# K1921VG015 register map
Vendor: NIIET; Series: K1921Vxxx; File version: 1.14
Registers are 32-bit, read-write, reset 0x0 unless marked. A register's access mark holds for its fields unless they carry their own. Offsets are from the block's base; [hi:lo] are bit positions; lines under a group give offsets from that group; {n}, {i} and the like mark numbered series.

## USB — USB control registers
Base 0x20010000
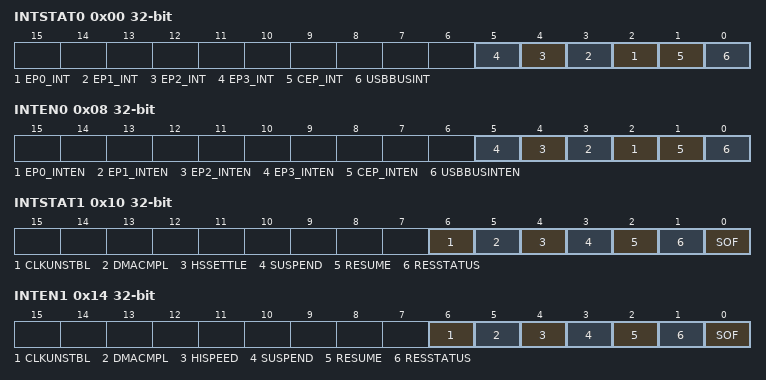
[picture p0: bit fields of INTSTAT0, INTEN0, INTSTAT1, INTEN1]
0x00 INTSTAT0 — Interrupt status register
  [n+2] EP{n}_INT (n=0..3) — Interrupt flags EndPoint {n}
  [1] CEP_INT — Interrupt flag Control EndPoint
  [0] USBBUSINT — Interrupt flag events on the USB bus
0x08 INTEN0 — Interrupt enable register
  [n+2] EP{n}_INTEN (n=0..3) — Interrupt enable for EndPoint {n}
  [1] CEP_INTEN — Interrupt enable for Control EndPoint
  [0] USBBUSINTEN — Enable interrupts from the events on the USB bus
0x10 INTSTAT1 — USB Interrupt status register
  [6] CLKUNSTBL — Interrupt flag, signaling an unstable clock signal UTMI and to initialize the device controller registers
  [5] DMACMPL — Completion flag DMA data transfer
  [4] HSSETTLE — Completion flag reset and switching devices in high-speed mode
  [3] SUSPEND — SUSPEND mode request bit
  [2] RESUME — Flag reactivate the device
  [1] RESSTATUS — Completion flag reset the root port
  [0] SOF — Flag SOF packet reception
0x14 INTEN1 — USB Interrupt enable register
  [6] CLKUNSTBL — Enable interrupt, signaling an unstable clock signal UTMI and to initialize the device controller registers
  [5] DMACMPL — Enable completion DMA data transfer
  [4] HISPEED — Enable completion reset and switching devices in high-speed mode
  [3] SUSPEND — Enable SUSPEND mode request bit
  [2] RESUME — Enable reactivate the device
  [1] RESSTATUS — Enable completion reset the root port
  [0] SOF — Enable SOF packet reception
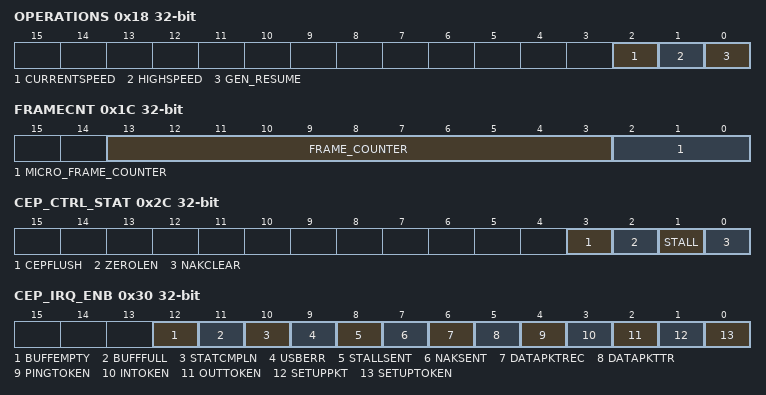
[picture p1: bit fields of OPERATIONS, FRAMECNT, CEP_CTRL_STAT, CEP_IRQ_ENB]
0x18 OPERATIONS — USB Operations register
  [2] CURRENTSPEED ro — Speed indication device controller 1-High speed; 0 - Full speed
  [1] HIGHSPEED ro — Trigger bit protocol 'Chirp'
  [0] GEN_RESUME — Bit start recovery work
0x1C FRAMECNT ro — USB Frame counter register
  [13:3] FRAME_COUNTER — Field frame counter since last SOF packet
  [2:0] MICRO_FRAME_COUNTER — Number field current a chip
0x20 USBADDR — USB Address register
  [6:0] USBADDR — Field of the current address of the device
0x28 CEP_DATA_BUF — Data buffer for transmission register of Control EndPoint
  [15:0] VAL — Data buffer for transmission
0x2C CEP_CTRL_STAT — Control register and buffer status of Control EndPoint
  [3] CEPFLUSH — Reset buffer
  [2] ZEROLEN — Enable transmission zero length packet
  [1] STALL — Enable sending 'Stall'
  [0] NAKCLEAR — Receiving flag tags SETIP
0x30 CEP_IRQ_ENB — Interrupt Enable buffer register of Control EndPoint
  [12] BUFFEMPTY — Enable flag emptying control buffer
  [11] BUFFFULL — Enable flag filling control buffer
  [10] STATCMPLN — Enable flag successful completion stage 'Status' operations on the USB bus
  [9] USBERR — Enable error flag during the operation
  [8] STALLSENT — Enable flag closure parcel labels STALL in response to mark IN or OUT
  [7] NAKSENT — Enable flag closure parcel labels NAK in response to mark IN or OUT
  [6] DATAPKTREC — Enable flag successful reception of the data packet following the label OUT, in response to which the mark has been sent ACK
  [5] DATAPKTTR — Enable flag successful sending of the data packet in response to the label to obtain IN ACK confirming tags
  [4] PINGTOKEN — Enable reception end flag tags PING from host
  [3] INTOKEN — Enable reception end flag tags IN from the host
  [2] OUTTOKEN — Enable reception end flag tags OUT from the host
  [1] SETUPPKT — Enable flag deadline Setup package from the host
  [0] SETUPTOKEN — Enable flag deadline tags SETUP from the host
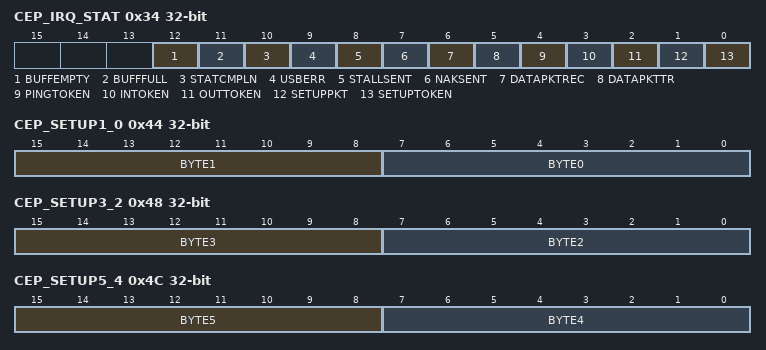
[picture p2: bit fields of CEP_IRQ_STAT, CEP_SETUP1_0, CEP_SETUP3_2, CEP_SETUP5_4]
0x34 CEP_IRQ_STAT — Buffer interrupt flag register of Control EndPoint
  [12] BUFFEMPTY ro — Flag control buffer emptying
  [11] BUFFFULL ro — Flag filling control buffer
  [10] STATCMPLN — Flag successful completion stage 'Status' operations on the USB bus
  [9] USBERR — The error flag during the operation
  [8] STALLSENT — Flag closure parcel labels STALL in response to mark IN or OUT
  [7] NAKSENT — Flag closure parcel labels NAK in response to mark IN or OUT
  [6] DATAPKTREC — Flag successful reception of the data packet following the label OUT, in response to which the mark has been sent ACK
  [5] DATAPKTTR — Flag successful sending of the data packet in response to the label to obtain IN ACK confirming tags
  [4] PINGTOKEN — Reception end flag tags PING from host
  [3] INTOKEN — Reception end flag tags IN from the host
  [2] OUTTOKEN — Reception end flag tags OUT from the host
  [1] SETUPPKT — Flag deadline Setup package from the host
  [0] SETUPTOKEN — Flag deadline tags SETUP from the host
0x38 CEP_IN_XFRCNT — In transfer data count register of Control EndPoint
  [7:0] DATACOUNT — The number of bytes to be sent in response to a label IN
0x3C CEP_OUT_XFRCNT ro — Out-transfer data count register of Control EndPoint
  [7:0] DATACOUNT — The number of bytes received of data
0x40 CEP_DATA_AVL ro — Register number of bytes received
  [15:0] NUM_BYTES — The number of bytes received of data
0x44 CEP_SETUP1_0 ro — Register zero and first byte packet Setup of Control EndPoint
  [15:8] BYTE1 — The first byte of the packet Setup
  [7:0] BYTE0 — destination
0x48 CEP_SETUP3_2 ro — Register 2nd and 3rd bytes of the packet Setup of Control EndPoint
  [15:8] BYTE3 — High byte field wValue
  [7:0] BYTE2 — Low byte field wValue
0x4C CEP_SETUP5_4 ro — Register 4th and 5th bytes of the packet Setup of Control EndPoint
  [15:8] BYTE5 — High byte field windex
  [7:0] BYTE4 — Low byte field windex
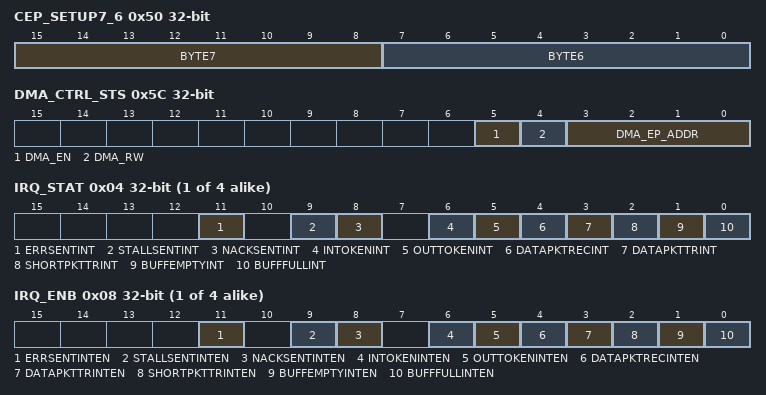
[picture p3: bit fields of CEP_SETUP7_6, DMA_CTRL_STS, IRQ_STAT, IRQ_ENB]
0x50 CEP_SETUP7_6 ro — Register on the 6th and 7th byte packet Setup of Control EndPoint
  [15:8] BYTE7 — High byte field wLength
  [7:0] BYTE6 — Low byte field wLength
0x54 CEP_START_ADDR — Control EndPoint RAM start Addr register
  [15:0] VAL — Beginning of the address space
0x58 CEP_END_ADDR — Control EndPoint RAM end Addr register
  [15:0] VAL — The end of the address space
0x5C DMA_CTRL_STS — DMA Control Register
  [5] DMA_EN — Enable DMA
  [4] DMA_RW — Type DMA operations 1-Read, 0-Write
  [3:0] DMA_EP_ADDR — Buffer address accessed by the DMA
0x60 DMA_CNT — DMA Count byte Register
  [15:0] DMA_CNT — The number of words transmitted by DMA
{0x70+0x40*i} USB_EP[{i}] (i=0..3) group
  0x00 DATA_BUF — EndPoint Data Register
    [15:0] DATA — Data exchange with the buffer
  0x04 IRQ_STAT — Interrupt flag register no control buffer
    [11] ERRSENTINT — Flag of any error during the operation
    [9] STALLSENTINT — Flag Uncommitted last packet
    [8] NACKSENTINT — Flag unsent last packet
    [6] INTOKENINT — Receiving flag tags IN from the host
    [5] OUTTOKENINT — Receiving flag tags OUT from the host
    [4] DATAPKTRECINT — Flag successful reception of a data packet from a host
    [3] DATAPKTTRINT — Flag to send a data packet from the buffer to the host
    [2] SHORTPKTTRINT — Flag size of the last packet
    [1] BUFFEMPTYINT ro — Buffer empty flag
    [0] BUFFFULLINT ro — Flag buffer fill
  0x08 IRQ_ENB — Enable register Interrupt no control buffer
    [11] ERRSENTINTEN — Enable flag of any error during the operation
    [9] STALLSENTINTEN — Enable flag Uncommitted last packet
    [8] NACKSENTINTEN — Enable flag unsent last packet
    [6] INTOKENINTEN — Enable receiving flag tags IN from the host
    [5] OUTTOKENINTEN — Enable receiving flag tags OUT from the host
    [4] DATAPKTRECINTEN — Enable flag successful reception of a data packet from a host
    [3] DATAPKTTRINTEN — Enable flag to send a data packet from the buffer to the host
    [2] SHORTPKTTRINTEN — Enable flag size of the last packet
    [1] BUFFEMPTYINTEN — Enable buffer empty flag
    [0] BUFFFULLINTEN — Enable flag buffer fill
  0x0C AVAIL_CNT ro — EndPoint Available count register
    [15:0] BUFFBYTENUM — Number of bytes in the buffer
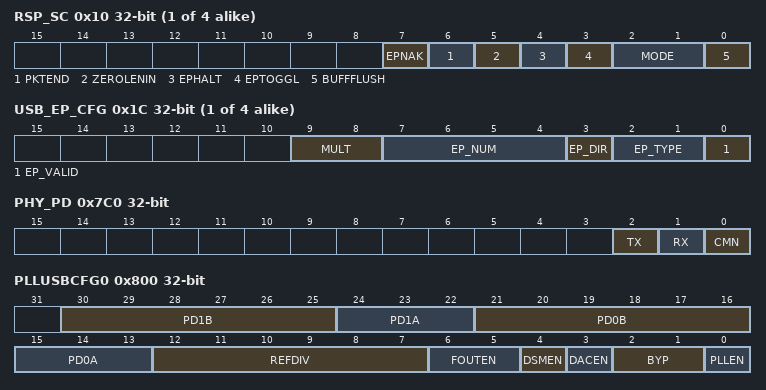
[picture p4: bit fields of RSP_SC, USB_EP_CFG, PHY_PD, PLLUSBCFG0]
  0x10 RSP_SC — EndPoint Response Set/Clear register
    [7] EPNAK — Select bit for NAK operation
    [6] PKTEND — Indicator number of bytes
    [5] ZEROLENIN — Select bit answer to mark IN
    [4] EPHALT — Select bit answer to any label from the host
    [3] EPTOGGL — Control bit by bit DATATOGGLE
    [2:1] MODE — Field mode of operation of the buffer type ID
      0=Auto-Validate mode; 1=Manual-Validate mode; 2=Fly (Fly mode)
    [0] BUFFFLUSH — Reset bit in the buffer and register EP_AVAIL_CNT
  0x14 MPS — EndPoint maximum packet size register
    [10:0] MAXPKTSIZE — Maximum packet size
  0x18 CNT — EndPoint Transfer count register
    [10:0] EP_TFR_CNT — Field number of bytes to send to the host mode Manual-Validate
  0x1C USB_EP_CFG — EndPoint configuration register
    [9:8] MULT — Field number of operations performed in one micro frame
      0=1 operation; 1=2 operation; 2=3 operation
    [7:4] EP_NUM — Number field buffer
    [3] EP_DIR — Field of type (direction) buffer
      0=OUT; 1=IN
    [2:1] EP_TYPE — Buffer type
      1=Bulk; 2=Int (Interrupt); 3=Isochronous
    [0] EP_VALID — Resolution of buffer
  0x20 START_ADDR — EndPoint RAM start addres register
    [9:0] STARTADDR — Start address space allocated for the buffer
  0x24 END_ADDR — EndPoint RAM end addres register
    [9:0] ENDADDR — The end of address space allocated for the buffer
0x700 AHB_DMA_ADDR — AHB addr register
  [31:0] AHBADDR — It specifies the address from which the DMA has to read / write.The address must WORD (32- bits) aligned
0x7C0 PHY_PD — USB PHY PowerDown Register
  [2] TX — Enable Powerdown of TX part
  [1] RX — Enable Powerdown of RX part
  [0] CMN — Enable powerdown function of common PHY logic
0x800 PLLUSBCFG0 — PLL configudration 0 register
  [30:25] PD1B
  [24:22] PD1A
  [21:16] PD0B
  [15:13] PD0A
  [12:7] REFDIV
  [6:5] FOUTEN — Output frequency enabled
  [4] DSMEN
  [3] DACEN
  [2:1] BYP — Bypass
  [0] PLLEN — PLL enable
0x804 PLLUSBCFG1 — PLL configudration 1 register
  [23:0] FRAC
0x808 PLLUSBCFG2 — PLL configudration 2 register
  [11:0] FBDIV
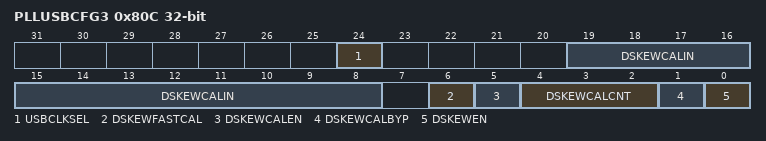
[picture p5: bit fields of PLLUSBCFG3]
0x80C PLLUSBCFG3 — PLL configudration 3 register
  [24] USBCLKSEL — 0-PLLUSBClk (FOUT0); 1- SYSClk
  [19:8] DSKEWCALIN
  [6] DSKEWFASTCAL
  [5] DSKEWCALEN
  [4:2] DSKEWCALCNT
  [1] DSKEWCALBYP
  [0] DSKEWEN
0x810 PLLUSBSTAT ro — PLL Status Register
  [0] LOCK — Lock status PLL
